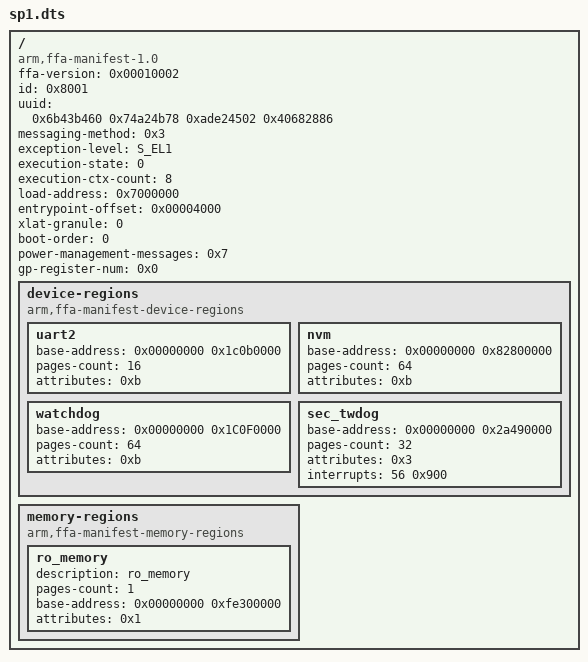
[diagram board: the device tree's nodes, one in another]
/*
 * Copyright (c) 2025, Arm Limited. All rights reserved.
 *
 * SPDX-License-Identifier: BSD-3-Clause
 */
/dts-v1/;

#define	AFF	00
#define S_EL0	(0x1)
#define S_EL1	(0x2)

/* For consumption by EL3 SPMC. */
/ {
	compatible = "arm,ffa-manifest-1.0";
	#address-cells = <2>;
	#size-cells = <1>;

	ffa-version = <0x00010002>; /* 31:16 - Major, 15:0 - Minor */
	id = <0x8001>;
	uuid = <0x6b43b460 0x74a24b78 0xade24502 0x40682886>;
	messaging-method = <0x3>; /* Direct Messaging Only */
	exception-level = <S_EL1>;
	execution-state = <0>;
	execution-ctx-count = <8>;
    load-address = <0x7000000>;
    entrypoint-offset = <0x00004000>;
    xlat-granule = <0>; /* 4KiB */
    boot-order = <0>;

	/* Subscribe to CPU_OFF, CPU_SUSPEND and CPU_SUSPEND_RESUME PM Msgs */
	power-management-messages = <0x7>;

    /* Boot protocol */
    gp-register-num = <0x0>;

    device-regions {
        compatible = "arm,ffa-manifest-device-regions";

        uart2 {
            base-address = <0x00000000 0x1c0b0000>;
            pages-count = <16>;
            attributes = <0xb>; /* NS-read-write */
        };

        nvm {
            base-address = <0x00000000 0x82800000>;
            pages-count = <64>;
            attributes = <0xb>; /* NS-read-write */
        };

        watchdog {
            base-address = <0x00000000 0x1C0F0000>;
            pages-count = <64>;
            attributes = <0xb>; /* NS-read-write */
        };

        sec_twdog {
            /* SP805 Trusted Watchdog Module */
            base-address = <0x00000000 0x2a490000>;
            pages-count = <32>; /* Two 64KB pages */
            attributes = <0x3>; /* read-write */
            interrupts = <56 0x900>;
        };

    };

    memory-regions {
        compatible = "arm,ffa-manifest-memory-regions";

        ro_memory: ro_memory {
                description = "ro_memory";
                pages-count = <1>;
                base-address = <0x00000000 0xfe300000>;
                attributes = <0x1>;  /* read-only */
        };
    };
};
